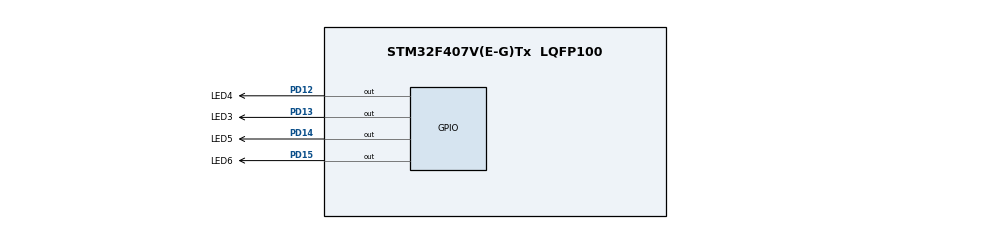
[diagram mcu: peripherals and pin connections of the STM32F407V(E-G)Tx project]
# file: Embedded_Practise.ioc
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FREERTOS.Tasks01=defaultTask,0,128,StartDefaultTask,Default,NULL,Dynamic,NULL,NULL
FREERTOS.configUSE_NEWLIB_REENTRANT=1
Mcu.Family=STM32F4
Mcu.Name=STM32F407V(E-G)Tx
Mcu.Package=LQFP100
NVIC.PriorityGroup=NVIC_PRIORITYGROUP_4
NVIC.TIM6_DAC_IRQn=true\:15\:0\:false\:false\:true\:false\:false\:true\:true
NVIC.TimeBase=TIM6_DAC_IRQn
NVIC.TimeBaseIP=TIM6
PA13.Mode=Serial_Wire
PA13.Signal=SYS_JTMS-SWDIO
PA14.Mode=Serial_Wire
PA14.Signal=SYS_JTCK-SWCLK
PD12.GPIO_Label=LED4
PD12.Signal=GPIO_Output
PD13.GPIO_Label=LED3
PD13.Signal=GPIO_Output
PD14.GPIO_Label=LED5
PD14.Signal=GPIO_Output
PD15.GPIO_Label=LED6
PD15.Signal=GPIO_Output
PH0-OSC_IN.Mode=HSE-External-Oscillator
PH0-OSC_IN.Signal=RCC_OSC_IN
PH1-OSC_OUT.Mode=HSE-External-Oscillator
PH1-OSC_OUT.Signal=RCC_OSC_OUT
ProjectManager.HeapSize=0x200
ProjectManager.StackSize=0x400
ProjectManager.TargetToolchain=STM32CubeIDE
RCC.48MHZClocksFreq_Value=48000000
RCC.AHBFreq_Value=168000000
RCC.APB1CLKDivider=RCC_HCLK_DIV4
RCC.APB1Freq_Value=42000000
RCC.APB1TimFreq_Value=84000000
RCC.APB2CLKDivider=RCC_HCLK_DIV2
RCC.APB2Freq_Value=84000000
RCC.APB2TimFreq_Value=168000000
RCC.CortexFreq_Value=168000000
RCC.HCLKFreq_Value=168000000
RCC.HSE_VALUE=8000000
RCC.HSI_VALUE=16000000
RCC.LSE_VALUE=32768
RCC.PLLM=4
RCC.PLLN=168
RCC.PLLQ=7
RCC.PLLSourceVirtual=RCC_PLLSOURCE_HSE
RCC.SYSCLKFreq_VALUE=168000000
RCC.SYSCLKSource=RCC_SYSCLKSOURCE_PLLCLK
RCC.VCOOutputFreq_Value=336000000
VP_FREERTOS_VS_CMSIS_V1.Mode=CMSIS_V1
VP_SYS_VS_tim6.Mode=TIM6
board=STM32F407G-DISC1

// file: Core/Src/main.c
/* USER CODE BEGIN Header */
/**
  ******************************************************************************
  * @file           : main.c
  * @brief          : Main program body
  ******************************************************************************
  * @attention
  *
  * Copyright (c) 2025 STMicroelectronics.
  * All rights reserved.
  *
  * This software is licensed under terms that can be found in the LICENSE file
  * in the root directory of this software component.
  * If no LICENSE file comes with this software, it is provided AS-IS.
  *
  ******************************************************************************
  */
/* USER CODE END Header */
#include "main.h"
#include "cmsis_os.h"

/* USER CODE BEGIN Includes */
#include "stdio.h"
#include "SEGGER_application.h"
#include "FREE_RTOS_application.h"
#include "portmacro.h"
/* USER CODE END Includes */

osThreadId defaultTaskHandle;

void SystemClock_Config(void);
static void MX_GPIO_Init(void);
void StartDefaultTask(void const * argument);

int main(void)
{

  /* USER CODE BEGIN 1 */
	DWT->CTRL |= (1<<0);
  /* USER CODE END 1 */

  /* MCU Configuration--------------------------------------------------------*/

  /* Reset of all peripherals, Initializes the Flash interface and the Systick. */
  HAL_Init();

  /* Configure the system clock */
  SystemClock_Config();

  /* Initialize all configured peripherals */
  MX_GPIO_Init();
  /* USER CODE BEGIN 2 */
  SEGGER_SYSVIEW_Conf();
  vSetVarulMaxPRIGROUPValue();
  SEGGER_SYSVIEW_Start();
  SEEGER_RTTInit();
  /* USER CODE END 2 */

  /* Create the thread(s) */
  /* definition and creation of defaultTask */
  osThreadDef(defaultTask, StartDefaultTask, osPriorityNormal, 0, 128);
  defaultTaskHandle = osThreadCreate(osThread(defaultTask), NULL);

  /* USER CODE BEGIN RTOS_THREADS */
  /* add threads, ... */
  callingTaskCreation();
  /* USER CODE END RTOS_THREADS */

  /* Start scheduler */
  osKernelStart();

  /* We should never get here as control is now taken by the scheduler */

  /* Infinite loop */
  while (1)
  {

    /* USER CODE BEGIN 3 */
	  orangeLed();   //default blinking 1ms
  }
  /* USER CODE END 3 */
}

void SystemClock_Config(void)
{
  LL_FLASH_SetLatency(LL_FLASH_LATENCY_5);
  while(LL_FLASH_GetLatency()!= LL_FLASH_LATENCY_5)
  {
  }
  LL_PWR_SetRegulVoltageScaling(LL_PWR_REGU_VOLTAGE_SCALE1);
  LL_RCC_HSE_Enable();

   /* Wait till HSE is ready */
  while(LL_RCC_HSE_IsReady() != 1)
  {

  }
  LL_RCC_PLL_ConfigDomain_SYS(LL_RCC_PLLSOURCE_HSE, LL_RCC_PLLM_DIV_4, 168, LL_RCC_PLLP_DIV_2);
  LL_RCC_PLL_Enable();

   /* Wait till PLL is ready */
  while(LL_RCC_PLL_IsReady() != 1)
  {

  }
  while (LL_PWR_IsActiveFlag_VOS() == 0)
  {
  }
  LL_RCC_SetAHBPrescaler(LL_RCC_SYSCLK_DIV_1);
  LL_RCC_SetAPB1Prescaler(LL_RCC_APB1_DIV_4);
  LL_RCC_SetAPB2Prescaler(LL_RCC_APB2_DIV_2);
  LL_RCC_SetSysClkSource(LL_RCC_SYS_CLKSOURCE_PLL);

   /* Wait till System clock is ready */
  while(LL_RCC_GetSysClkSource() != LL_RCC_SYS_CLKSOURCE_STATUS_PLL)
  {

  }
  LL_SetSystemCoreClock(168000000);

   /* Update the time base */
  if (HAL_InitTick (TICK_INT_PRIORITY) != HAL_OK)
  {
    Error_Handler();
  }
}

static void MX_GPIO_Init(void)
{
  LL_GPIO_InitTypeDef GPIO_InitStruct = {0};

  /* GPIO Ports Clock Enable */
  LL_AHB1_GRP1_EnableClock(LL_AHB1_GRP1_PERIPH_GPIOH);
  LL_AHB1_GRP1_EnableClock(LL_AHB1_GRP1_PERIPH_GPIOD);
  LL_AHB1_GRP1_EnableClock(LL_AHB1_GRP1_PERIPH_GPIOA);

  /**/
  LL_GPIO_ResetOutputPin(GPIOD, LED4_Pin|LED3_Pin|LED5_Pin|LED6_Pin);

  /**/
  GPIO_InitStruct.Pin = LED4_Pin|LED3_Pin|LED5_Pin|LED6_Pin;
  GPIO_InitStruct.Mode = LL_GPIO_MODE_OUTPUT;
  GPIO_InitStruct.Speed = LL_GPIO_SPEED_FREQ_LOW;
  GPIO_InitStruct.OutputType = LL_GPIO_OUTPUT_PUSHPULL;
  GPIO_InitStruct.Pull = LL_GPIO_PULL_NO;
  LL_GPIO_Init(GPIOD, &GPIO_InitStruct);

}

void StartDefaultTask(void const * argument)
{
  for(;;)
  {
    osDelay(1);
  }
}

void HAL_TIM_PeriodElapsedCallback(TIM_HandleTypeDef *htim)
{
  if (htim->Instance == TIM6)
  {
    HAL_IncTick();
  }
}

void Error_Handler(void)
{
  __disable_irq();
  while (1)
  {
  }
}
